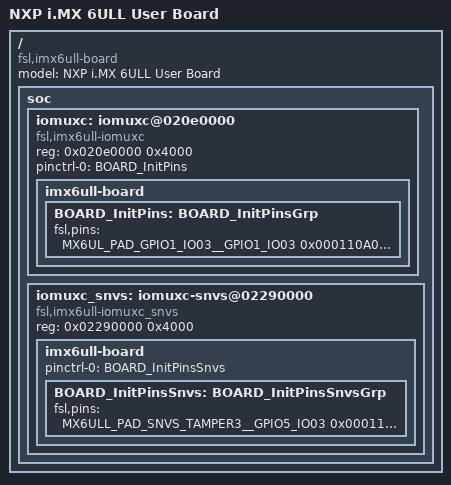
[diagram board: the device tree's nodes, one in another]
/***********************************************************************************************************************
 * This file was generated by the MCUXpresso Config Tools. Any manual edits made to this file
 * will be overwritten if the respective MCUXpresso Config Tools is used to update this file.
 **********************************************************************************************************************/

/*
 * TEXT BELOW IS USED AS SETTING FOR TOOLS *************************************
!!GlobalInfo
product: Pins v9.0
processor: MCIMX6Y2xxx08
package_id: MCIMX6Y2CVM08
mcu_data: i_mx_2_0
processor_version: 9.0.0
 * BE CAREFUL MODIFYING THIS COMMENT - IT IS YAML SETTINGS FOR TOOLS ***********
 */

/*
 * TEXT BELOW IS USED AS SETTING FOR TOOLS *************************************
BOARD_InitPins:
- options: {callFromInitBoot: 'false', coreID: ca7}
- pin_list:
  - {pin_num: P10, peripheral: GPIO5, signal: 'gpio_io, 3', pin_signal: SNVS_TAMPER3, direction: OUTPUT, HYS: ENABLED}
  - {pin_num: L17, peripheral: GPIO1, signal: 'gpio_io, 3', pin_signal: GPIO1_IO03, direction: OUTPUT, HYS: ENABLED, DSE: OHM_60}
  - {pin_num: M16, peripheral: GPIO1, signal: 'gpio_io, 4', pin_signal: GPIO1_IO04, direction: OUTPUT, HYS: ENABLED, DSE: OHM_60}
 * BE CAREFUL MODIFYING THIS COMMENT - IT IS YAML SETTINGS FOR TOOLS ***********
 */

/dts-v1/;

#include "skeleton.dtsi"
#include "imx6ull-pinfunc.h"
#include "imx6ull-pinfunc-snvs.h"

/ {
    model = "NXP i.MX 6ULL User Board";
    compatible = "fsl,imx6ull-board", "fsl,imx6ull";

    soc {
        #address-cells = <1>;
        #size-cells = <1>;

        iomuxc: iomuxc@020e0000 {
            compatible = "fsl,imx6ull-iomuxc";
            reg = <0x020e0000 0x4000>;
        };

        iomuxc_snvs: iomuxc-snvs@02290000 {
            compatible = "fsl,imx6ull-iomuxc_snvs";
            reg = <0x02290000 0x4000>;
        };
    };
};

&iomuxc {
    pinctrl-names = "default";
    pinctrl-0 = <&BOARD_InitPins>;
    imx6ull-board {
        BOARD_InitPins: BOARD_InitPinsGrp {                /*!< Function assigned for the core: Cortex-A7[ca7] */
            fsl,pins = <
                MX6UL_PAD_GPIO1_IO03__GPIO1_IO03           0x000110A0
                MX6UL_PAD_GPIO1_IO04__GPIO1_IO04           0x000110A0
            >;
        };
    };
};

&iomuxc_snvs {
    pinctrl-names = "default_snvs";
    imx6ull-board {
    pinctrl-0 = <&BOARD_InitPinsSnvs>;
        BOARD_InitPinsSnvs: BOARD_InitPinsSnvsGrp {        /*!< Function assigned for the core: Cortex-A7[ca7] */
            fsl,pins = <
                MX6ULL_PAD_SNVS_TAMPER3__GPIO5_IO03        0x000110A0
            >;
        };
    };
};

